# STM32C5A3xx register map
File version: 1.0
Registers are 32-bit, read-write, reset 0x0 unless marked. A register's access mark holds for its fields unless they carry their own. Offsets are from the block's base; [hi:lo] are bit positions.

## EXITHDPLIB_PFUNC — EXITHDPLIB function pointer structure
Base 0x0BF883E0
0x0C JumpHDPLvl2
0x10 JumpHDPLvl3

## WWDG
Base 0x40002C00
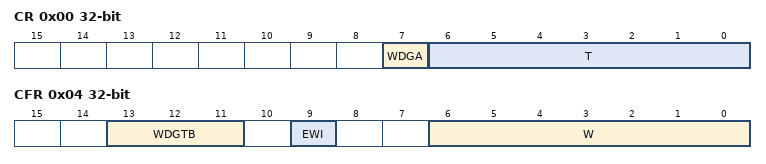
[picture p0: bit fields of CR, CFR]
0x00 CR — WWDG Control register
  [7] WDGA — Activation bit
  [6:0] T — T[6:0] bits (7-Bit counter (MSB to LSB))
0x04 CFR — WWDG Configuration register
  [13:11] WDGTB — WDGTB[2:0] bits (Timer Base)
  [9] EWI — Early Wakeup Interrupt
  [6:0] W — W[6:0] bits (7-bit window value)
0x08 SR — WWDG Status register
  [0] EWIF — Early Wakeup Interrupt Flag

## IWDG
Base 0x40003000
0x00 KR — IWDG Key register
  [15:0] KEY — Key value (write only, read 0000h)
0x04 PR — IWDG Prescaler register
  [3:0] PR — PR[3:0] (Prescaler divider)
0x08 RLR — IWDG Reload register
  [11:0] RL — Watchdog counter reload value
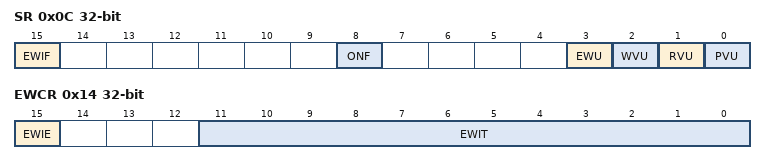
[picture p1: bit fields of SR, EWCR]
0x0C SR ro — IWDG Status register
  [15] EWIF — Watchdog early interrupt flag
  [8] ONF — Watchdog enable flag
  [3] EWU — Watchdog interrupt comparator value update
  [2] WVU — Watchdog counter window value update
  [1] RVU — Watchdog counter reload value update
  [0] PVU — Watchdog prescaler value update
0x10 WINR — IWDG Window register
  [11:0] WIN — Watchdog counter window value
0x14 EWCR — IWDG Early Wakeup register
  [15] EWIE — Watchdog early wakeup comparator value
  [11:0] EWIT — Watchdog early wakeup comparator value
0x18 ICR — IWDG interrupt clear register
  [15] EWIC — Watchdog early interrupt acknowledge

## COMP1 — Comparator
Base 0x40004000
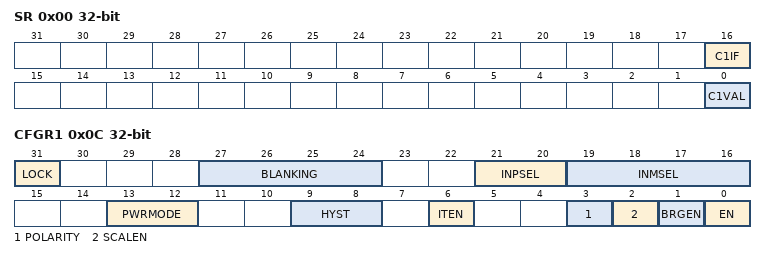
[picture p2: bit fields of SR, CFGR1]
0x00 SR ro — Comparator status register
  [16] C1IF, [0] C1VAL
0x04 ICFR — Comparator interrupt clear flag register
  [16] CC1IF
0x0C CFGR1 — Comparator configuration register 1
  [31] LOCK — Comparator lock
  [27:24] BLANKING — Comparator blanking source selection
  [21:20] INPSEL — Comparator input plus selection
  [19:16] INMSEL — Comparator input minus selection
  [13:12] PWRMODE — Comparator power mode selection
  [9:8] HYST — Comparator hysteresis selection
  [6] ITEN — Comparator interrupt enable
  [3] POLARITY — Comparator polarity selection
  [2] SCALEN — Comparator voltage scaler enable
  [1] BRGEN — Comparator scaler bridge enable
  [0] EN — Comparator enable
0x10 CFGR2 — Comparator configuration register 2

## I2C1 — Inter-integrated Circuit Interface
Base 0x40005400
Same registers: I2C2 0x40005800
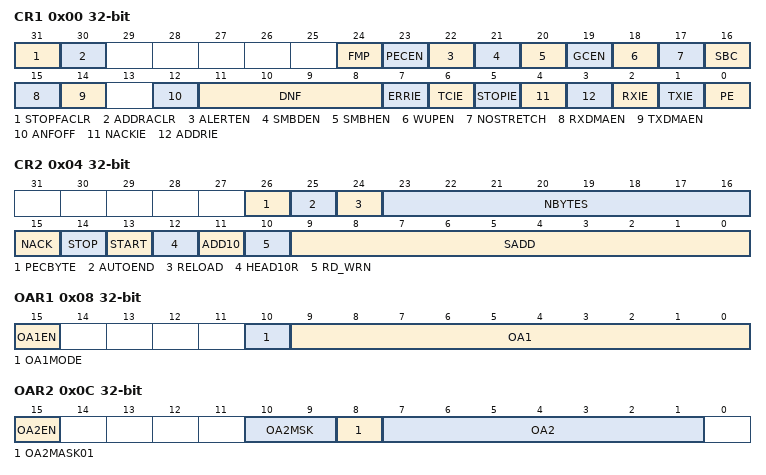
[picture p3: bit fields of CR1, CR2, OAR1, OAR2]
0x00 CR1 — I2C Control register 1
  [31] STOPFACLR — STOPFACLR enable
  [30] ADDRACLR — ADDRACLR enable
  [24] FMP — Fast-mode Plus 20 mA drive enable
  [23] PECEN — PEC enable
  [22] ALERTEN — SMBus alert enable
  [21] SMBDEN — SMBus device default address enable
  [20] SMBHEN — SMBus host address enable
  [19] GCEN — General call enable
  [18] WUPEN — Wakeup from STOP enable
  [17] NOSTRETCH — Clock stretching disable
  [16] SBC — Slave byte control
  [15] RXDMAEN — DMA reception requests enable
  [14] TXDMAEN — DMA transmission requests enable
  [12] ANFOFF — Analog noise filter OFF
  [11:8] DNF — Digital noise filter
  [7] ERRIE — Errors interrupt enable
  [6] TCIE — Transfer complete interrupt enable
  [5] STOPIE — STOP detection interrupt enable
  [4] NACKIE — NACK received interrupt enable
  [3] ADDRIE — Address match interrupt enable
  [2] RXIE — RX interrupt enable
  [1] TXIE — TX interrupt enable
  [0] PE — Peripheral enable
0x04 CR2 — I2C Control register 2
  [26] PECBYTE — Packet error checking byte
  [25] AUTOEND — Automatic end mode (master mode)
  [24] RELOAD — NBYTES reload mode
  [23:16] NBYTES — Number of bytes
  [15] NACK — NACK generation (slave mode)
  [14] STOP — STOP generation (master mode)
  [13] START — START generation
  [12] HEAD10R — 10-bit address header only read direction (master mode)
  [11] ADD10 — 10-bit addressing mode (master mode)
  [10] RD_WRN — Transfer direction (master mode)
  [9:0] SADD — Slave address (master mode)
0x08 OAR1 — I2C Own address 1 register
  [15] OA1EN — Own address 1 enable
  [10] OA1MODE — Own address 1 10-bit mode
  [9:0] OA1 — Interface own address 1
0x0C OAR2 — I2C Own address 2 register
  [15] OA2EN — Own address 2 enable
  [10:9] OA2MSK — Own address 2 masks
  [8] OA2MASK01 — OA2[1] is masked, Only OA2[7:2] are compared
  [7:1] OA2 — Interface own address 2
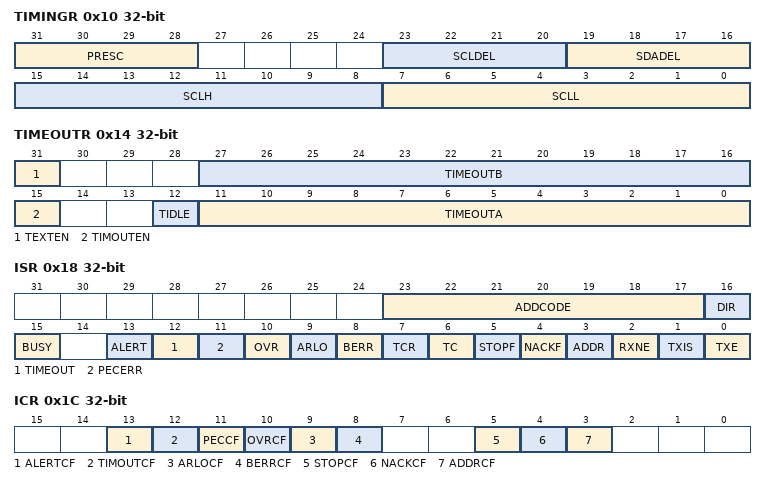
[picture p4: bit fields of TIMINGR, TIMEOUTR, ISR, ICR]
0x10 TIMINGR — I2C Timing register
  [31:28] PRESC — Timings prescaler
  [23:20] SCLDEL — Data setup time
  [19:16] SDADEL — Data hold time
  [15:8] SCLH — SCL high period (master mode)
  [7:0] SCLL — SCL low period (master mode)
0x14 TIMEOUTR — I2C Timeout register
  [31] TEXTEN — Extended clock timeout enable
  [27:16] TIMEOUTB — Bus timeout B
  [15] TIMOUTEN — Clock timeout enable
  [12] TIDLE — Idle clock timeout detection
  [11:0] TIMEOUTA — Bus timeout A
0x18 ISR — I2C Interrupt and status register
  [23:17] ADDCODE — Address match code (slave mode)
  [16] DIR — Transfer direction (slave mode)
  [15] BUSY — Bus busy
  [13] ALERT — SMBus alert
  [12] TIMEOUT — Timeout or Tlow detection flag
  [11] PECERR — PEC error in reception
  [10] OVR — Overrun/Underrun
  [9] ARLO — Arbitration lost
  [8] BERR — Bus error
  [7] TCR — Transfer complete reload
  [6] TC — Transfer complete (master mode)
  [5] STOPF — STOP detection flag
  [4] NACKF — NACK received flag
  [3] ADDR — Address matched (slave mode)
  [2] RXNE — Receive data register not empty
  [1] TXIS — Transmit interrupt status
  [0] TXE — Transmit data register empty
0x1C ICR — I2C Interrupt clear register
  [13] ALERTCF — Alert clear flag
  [12] TIMOUTCF — Timeout clear flag
  [11] PECCF — PAC error clear flag
  [10] OVRCF — Overrun/Underrun clear flag
  [9] ARLOCF — Arbitration lost clear flag
  [8] BERRCF — Bus error clear flag
  [5] STOPCF — STOP detection clear flag
  [4] NACKCF — NACK clear flag
  [3] ADDRCF — Address matched clear flag
0x20 PECR ro — I2C PEC register
  [7:0] PEC
0x24 RXDR ro — I2C Receive data register
  [7:0] RXDATA — 8-bit receive data
0x28 TXDR — I2C Transmit data register
  [7:0] TXDATA — 8-bit transmit data
